# SYSCTRL_PADCONF_CORE register map
Vendor: Texas Instruments
Registers are 32-bit, access per field, reset 0x10F010F unless marked. A register's access mark holds for its fields unless they carry their own. Offsets are as the file gives them; [hi:lo] are bit positions; 'fields as' and 'values as' point back to an identical list.

## SYSCTRL_PADCONF_CORE (part 8 of 10)
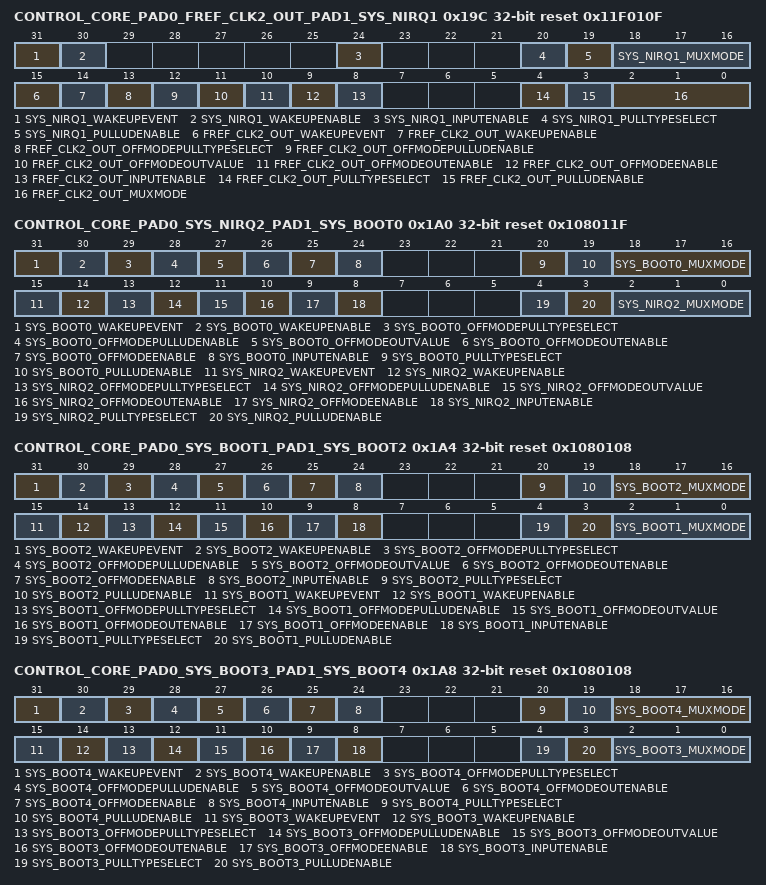
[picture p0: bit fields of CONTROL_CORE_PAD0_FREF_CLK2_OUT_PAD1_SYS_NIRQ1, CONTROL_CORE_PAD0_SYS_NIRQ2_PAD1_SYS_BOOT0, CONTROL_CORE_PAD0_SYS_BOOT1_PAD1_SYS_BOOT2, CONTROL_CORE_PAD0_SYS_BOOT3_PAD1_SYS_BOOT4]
0x19C CONTROL_CORE_PAD0_FREF_CLK2_OUT_PAD1_SYS_NIRQ1 reset 0x11F010F — Register control for Pads fref_clk2_out and sys_nirq1 Access conditions. Read: unrestricted, Write: unrestricted
  [31] SYS_NIRQ1_WAKEUPEVENT ro — Pad_x wake-up event status latched in the IO
    0=SYS_NIRQ1_WAKEUPEVENT_0_r (No wake-up event occurred); 1=SYS_NIRQ1_WAKEUPEVENT_1_r (A wake-up event occurred)
  [30] SYS_NIRQ1_WAKEUPENABLE rw — Input pad wake-up enable (and OFF mode input enable value)
    0=wake-up detection is disabled; 1=wake-up detection is enabled
  [24] SYS_NIRQ1_INPUTENABLE rw — Input enable value for pad sys_nirq1
    0=Input buffer of I/O cell is disabled; 1=Input buffer of I/O cell is enabled
  [20] SYS_NIRQ1_PULLTYPESELECT rw — pullup/down selection for pad sys_nirq1
    0=pulldown selected; 1=pullup selected
  [19] SYS_NIRQ1_PULLUDENABLE rw — pullup/down enable for pad sys_nirq1
    0=pullup/down disabled; 1=pullup/down enabled
  [18:16] SYS_NIRQ1_MUXMODE rw — Functional multiplexing selection for pad sys_nirq1
    0=Select sys_nirq1; 7=Select safe_mode
  [15] FREF_CLK2_OUT_WAKEUPEVENT ro — Pad_x wake-up event status latched in the IO
    0=FREF_CLK2_OUT_WAKEUPEVENT_0_r (No wake-up event occurred); 1=FREF_CLK2_OUT_WAKEUPEVENT_1_r (A wake-up event occurred)
  [14] FREF_CLK2_OUT_WAKEUPENABLE rw — Input pad wake-up enable (and OFF mode input enable value)
    values as SYS_NIRQ1_WAKEUPENABLE
  [13] FREF_CLK2_OUT_OFFMODEPULLTYPESELECT rw — OffMode mode pullup/down selection for pad fref_clk2_out
    0=Offmode pulldown selected; 1=Offmode pullup selected
  [12] FREF_CLK2_OUT_OFFMODEPULLUDENABLE rw — OffMode mode pullup/down enable for pad fref_clk2_out
    0=Offmode pullup/down disabled; 1=Offmode pullup/down enabled
  [11] FREF_CLK2_OUT_OFFMODEOUTVALUE rw — OffMode mode output value for pad fref_clk2_out
    0=Set value at 0; 1=Set value at 1
  [10] FREF_CLK2_OUT_OFFMODEOUTENABLE rw — OffMode mode output enable value for pad fref_clk2_out. This is an active low signal
    0=Output enable; 1=Output disable
  [9] FREF_CLK2_OUT_OFFMODEENABLE rw — OffMode mode override control for pad fref_clk2_out
    0=I/O state keeps its previous state when OFF mode is active; 1=I/O state is forced to OFF mode value when OFF mode is active
  [8] FREF_CLK2_OUT_INPUTENABLE rw — Input enable value for pad fref_clk2_out
    values as SYS_NIRQ1_INPUTENABLE
  [4] FREF_CLK2_OUT_PULLTYPESELECT rw — pullup/down selection for pad fref_clk2_out
    0=pulldown selected; 1=pullup selected
  [3] FREF_CLK2_OUT_PULLUDENABLE rw — pullup/down enable for pad fref_clk2_out
    0=pullup/down disabled; 1=pullup/down enabled
  [2:0] FREF_CLK2_OUT_MUXMODE rw — Functional multiplexing selection for pad fref_clk2_out
    0=Select fref_clk2_out; 3=Select gpio_182; 7=Select safe_mode
0x1A0 CONTROL_CORE_PAD0_SYS_NIRQ2_PAD1_SYS_BOOT0 reset 0x108011F — Register control for Pads sys_nirq2 and sys_boot0 Access conditions. Read: unrestricted, Write: unrestricted
  [31] SYS_BOOT0_WAKEUPEVENT ro — Pad_x wake-up event status latched in the IO
    0=SYS_BOOT0_WAKEUPEVENT_0_r (No wake-up event occurred); 1=SYS_BOOT0_WAKEUPEVENT_1_r (A wake-up event occurred)
  [30] SYS_BOOT0_WAKEUPENABLE rw — Input pad wake-up enable (and OFF mode input enable value)
    values as CONTROL_CORE_PAD0_FREF_CLK2_OUT_PAD1_SYS_NIRQ1.SYS_NIRQ1_WAKEUPENABLE
  [29] SYS_BOOT0_OFFMODEPULLTYPESELECT rw — OffMode mode pullup/down selection for pad sys_boot0
    0=Offmode pulldown selected; 1=Offmode pullup selected
  [28] SYS_BOOT0_OFFMODEPULLUDENABLE rw — OffMode mode pullup/down enable for pad sys_boot0
    values as CONTROL_CORE_PAD0_FREF_CLK2_OUT_PAD1_SYS_NIRQ1.FREF_CLK2_OUT_OFFMODEPULLUDENABLE
  [27] SYS_BOOT0_OFFMODEOUTVALUE rw — OffMode mode output value for pad sys_boot0
    0=Set value at 0; 1=Set value at 1
  [26] SYS_BOOT0_OFFMODEOUTENABLE rw — OffMode mode output enable value for pad sys_boot0. This is an active low signal
    0=Output enable; 1=Output disable
  [25] SYS_BOOT0_OFFMODEENABLE rw — OffMode mode override control for pad sys_boot0
    values as CONTROL_CORE_PAD0_FREF_CLK2_OUT_PAD1_SYS_NIRQ1.FREF_CLK2_OUT_OFFMODEENABLE
  [24] SYS_BOOT0_INPUTENABLE rw — Input enable value for pad sys_boot0
    values as CONTROL_CORE_PAD0_FREF_CLK2_OUT_PAD1_SYS_NIRQ1.SYS_NIRQ1_INPUTENABLE
  [20] SYS_BOOT0_PULLTYPESELECT rw — pullup/down selection for pad sys_boot0
    0=pulldown selected; 1=pullup selected
  [19] SYS_BOOT0_PULLUDENABLE rw — pullup/down enable for pad sys_boot0
    0=pullup/down disabled; 1=pullup/down enabled
  [18:16] SYS_BOOT0_MUXMODE rw — Functional multiplexing selection for pad sys_boot0
    0=Select sys_boot0; 3=Select gpio_184; 7=Select safe_mode
  [15] SYS_NIRQ2_WAKEUPEVENT ro — Pad_x wake-up event status latched in the IO
    0=SYS_NIRQ2_WAKEUPEVENT_0_r (No wake-up event occurred); 1=SYS_NIRQ2_WAKEUPEVENT_1_r (A wake-up event occurred)
  [14] SYS_NIRQ2_WAKEUPENABLE rw — Input pad wake-up enable (and OFF mode input enable value)
    values as CONTROL_CORE_PAD0_FREF_CLK2_OUT_PAD1_SYS_NIRQ1.SYS_NIRQ1_WAKEUPENABLE
  [13] SYS_NIRQ2_OFFMODEPULLTYPESELECT rw — OffMode mode pullup/down selection for pad sys_nirq2
    0=Offmode pulldown selected; 1=Offmode pullup selected
  [12] SYS_NIRQ2_OFFMODEPULLUDENABLE rw — OffMode mode pullup/down enable for pad sys_nirq2
    values as CONTROL_CORE_PAD0_FREF_CLK2_OUT_PAD1_SYS_NIRQ1.FREF_CLK2_OUT_OFFMODEPULLUDENABLE
  [11] SYS_NIRQ2_OFFMODEOUTVALUE rw — OffMode mode output value for pad sys_nirq2
    0=Set value at 0; 1=Set value at 1
  [10] SYS_NIRQ2_OFFMODEOUTENABLE rw — OffMode mode output enable value for pad sys_nirq2. This is an active low signal
    0=Output enable; 1=Output disable
  [9] SYS_NIRQ2_OFFMODEENABLE rw — OffMode mode override control for pad sys_nirq2
    values as CONTROL_CORE_PAD0_FREF_CLK2_OUT_PAD1_SYS_NIRQ1.FREF_CLK2_OUT_OFFMODEENABLE
  [8] SYS_NIRQ2_INPUTENABLE rw — Input enable value for pad sys_nirq2
    values as CONTROL_CORE_PAD0_FREF_CLK2_OUT_PAD1_SYS_NIRQ1.SYS_NIRQ1_INPUTENABLE
  [4] SYS_NIRQ2_PULLTYPESELECT rw — pullup/down selection for pad sys_nirq2
    0=pulldown selected; 1=pullup selected
  [3] SYS_NIRQ2_PULLUDENABLE rw — pullup/down enable for pad sys_nirq2
    0=pullup/down disabled; 1=pullup/down enabled
  [2:0] SYS_NIRQ2_MUXMODE rw — Functional multiplexing selection for pad sys_nirq2
    0=Select sys_nirq2; 3=Select gpio_183; 7=Select safe_mode
0x1A4 CONTROL_CORE_PAD0_SYS_BOOT1_PAD1_SYS_BOOT2 reset 0x1080108 — Register control for Pads sys_boot1 and sys_boot2 Access conditions. Read: unrestricted, Write: unrestricted
  [31] SYS_BOOT2_WAKEUPEVENT ro — Pad_x wake-up event status latched in the IO
    0=SYS_BOOT2_WAKEUPEVENT_0_r (No wake-up event occurred); 1=SYS_BOOT2_WAKEUPEVENT_1_r (A wake-up event occurred)
  [30] SYS_BOOT2_WAKEUPENABLE rw — Input pad wake-up enable (and OFF mode input enable value)
    values as CONTROL_CORE_PAD0_FREF_CLK2_OUT_PAD1_SYS_NIRQ1.SYS_NIRQ1_WAKEUPENABLE
  [29] SYS_BOOT2_OFFMODEPULLTYPESELECT rw — OffMode mode pullup/down selection for pad sys_boot2
    0=Offmode pulldown selected; 1=Offmode pullup selected
  [28] SYS_BOOT2_OFFMODEPULLUDENABLE rw — OffMode mode pullup/down enable for pad sys_boot2
    values as CONTROL_CORE_PAD0_FREF_CLK2_OUT_PAD1_SYS_NIRQ1.FREF_CLK2_OUT_OFFMODEPULLUDENABLE
  [27] SYS_BOOT2_OFFMODEOUTVALUE rw — OffMode mode output value for pad sys_boot2
    0=Set value at 0; 1=Set value at 1
  [26] SYS_BOOT2_OFFMODEOUTENABLE rw — OffMode mode output enable value for pad sys_boot2. This is an active low signal
    0=Output enable; 1=Output disable
  [25] SYS_BOOT2_OFFMODEENABLE rw — OffMode mode override control for pad sys_boot2
    values as CONTROL_CORE_PAD0_FREF_CLK2_OUT_PAD1_SYS_NIRQ1.FREF_CLK2_OUT_OFFMODEENABLE
  [24] SYS_BOOT2_INPUTENABLE rw — Input enable value for pad sys_boot2
    values as CONTROL_CORE_PAD0_FREF_CLK2_OUT_PAD1_SYS_NIRQ1.SYS_NIRQ1_INPUTENABLE
  [20] SYS_BOOT2_PULLTYPESELECT rw — pullup/down selection for pad sys_boot2
    0=pulldown selected; 1=pullup selected
  [19] SYS_BOOT2_PULLUDENABLE rw — pullup/down enable for pad sys_boot2
    0=pullup/down disabled; 1=pullup/down enabled
  [18:16] SYS_BOOT2_MUXMODE rw — Functional multiplexing selection for pad sys_boot2
    0=Select sys_boot2; 3=Select gpio_186; 7=Select safe_mode
  [15] SYS_BOOT1_WAKEUPEVENT ro — Pad_x wake-up event status latched in the IO
    0=SYS_BOOT1_WAKEUPEVENT_0_r (No wake-up event occurred); 1=SYS_BOOT1_WAKEUPEVENT_1_r (A wake-up event occurred)
  [14] SYS_BOOT1_WAKEUPENABLE rw — Input pad wake-up enable (and OFF mode input enable value)
    values as CONTROL_CORE_PAD0_FREF_CLK2_OUT_PAD1_SYS_NIRQ1.SYS_NIRQ1_WAKEUPENABLE
  [13] SYS_BOOT1_OFFMODEPULLTYPESELECT rw — OffMode mode pullup/down selection for pad sys_boot1
    0=Offmode pulldown selected; 1=Offmode pullup selected
  [12] SYS_BOOT1_OFFMODEPULLUDENABLE rw — OffMode mode pullup/down enable for pad sys_boot1
    values as CONTROL_CORE_PAD0_FREF_CLK2_OUT_PAD1_SYS_NIRQ1.FREF_CLK2_OUT_OFFMODEPULLUDENABLE
  [11] SYS_BOOT1_OFFMODEOUTVALUE rw — OffMode mode output value for pad sys_boot1
    0=Set value at 0; 1=Set value at 1
  [10] SYS_BOOT1_OFFMODEOUTENABLE rw — OffMode mode output enable value for pad sys_boot1. This is an active low signal
    0=Output enable; 1=Output disable
  [9] SYS_BOOT1_OFFMODEENABLE rw — OffMode mode override control for pad sys_boot1
    values as CONTROL_CORE_PAD0_FREF_CLK2_OUT_PAD1_SYS_NIRQ1.FREF_CLK2_OUT_OFFMODEENABLE
  [8] SYS_BOOT1_INPUTENABLE rw — Input enable value for pad sys_boot1
    values as CONTROL_CORE_PAD0_FREF_CLK2_OUT_PAD1_SYS_NIRQ1.SYS_NIRQ1_INPUTENABLE
  [4] SYS_BOOT1_PULLTYPESELECT rw — pullup/down selection for pad sys_boot1
    0=pulldown selected; 1=pullup selected
  [3] SYS_BOOT1_PULLUDENABLE rw — pullup/down enable for pad sys_boot1
    0=pullup/down disabled; 1=pullup/down enabled
  [2:0] SYS_BOOT1_MUXMODE rw — Functional multiplexing selection for pad sys_boot1
    0=Select sys_boot1; 3=Select gpio_185; 7=Select safe_mode
0x1A8 CONTROL_CORE_PAD0_SYS_BOOT3_PAD1_SYS_BOOT4 reset 0x1080108 — Register control for Pads sys_boot3 and sys_boot4 Access conditions. Read: unrestricted, Write: unrestricted
  [31] SYS_BOOT4_WAKEUPEVENT ro — Pad_x wake-up event status latched in the IO
    0=SYS_BOOT4_WAKEUPEVENT_0_r (No wake-up event occurred); 1=SYS_BOOT4_WAKEUPEVENT_1_r (A wake-up event occurred)
  [30] SYS_BOOT4_WAKEUPENABLE rw — Input pad wake-up enable (and OFF mode input enable value)
    values as CONTROL_CORE_PAD0_FREF_CLK2_OUT_PAD1_SYS_NIRQ1.SYS_NIRQ1_WAKEUPENABLE
  [29] SYS_BOOT4_OFFMODEPULLTYPESELECT rw — OffMode mode pullup/down selection for pad sys_boot4
    0=Offmode pulldown selected; 1=Offmode pullup selected
  [28] SYS_BOOT4_OFFMODEPULLUDENABLE rw — OffMode mode pullup/down enable for pad sys_boot4
    values as CONTROL_CORE_PAD0_FREF_CLK2_OUT_PAD1_SYS_NIRQ1.FREF_CLK2_OUT_OFFMODEPULLUDENABLE
  [27] SYS_BOOT4_OFFMODEOUTVALUE rw — OffMode mode output value for pad sys_boot4
    0=Set value at 0; 1=Set value at 1
  [26] SYS_BOOT4_OFFMODEOUTENABLE rw — OffMode mode output enable value for pad sys_boot4. This is an active low signal
    0=Output enable; 1=Output disable
  [25] SYS_BOOT4_OFFMODEENABLE rw — OffMode mode override control for pad sys_boot4
    values as CONTROL_CORE_PAD0_FREF_CLK2_OUT_PAD1_SYS_NIRQ1.FREF_CLK2_OUT_OFFMODEENABLE
  [24] SYS_BOOT4_INPUTENABLE rw — Input enable value for pad sys_boot4
    values as CONTROL_CORE_PAD0_FREF_CLK2_OUT_PAD1_SYS_NIRQ1.SYS_NIRQ1_INPUTENABLE
  [20] SYS_BOOT4_PULLTYPESELECT rw — pullup/down selection for pad sys_boot4
    0=pulldown selected; 1=pullup selected
  [19] SYS_BOOT4_PULLUDENABLE rw — pullup/down enable for pad sys_boot4
    0=pullup/down disabled; 1=pullup/down enabled
  [18:16] SYS_BOOT4_MUXMODE rw — Functional multiplexing selection for pad sys_boot4
    0=Select sys_boot4; 3=Select gpio_188; 7=Select safe_mode
  [15] SYS_BOOT3_WAKEUPEVENT ro — Pad_x wake-up event status latched in the IO
    0=SYS_BOOT3_WAKEUPEVENT_0_r (No wake-up event occurred); 1=SYS_BOOT3_WAKEUPEVENT_1_r (A wake-up event occurred)
  [14] SYS_BOOT3_WAKEUPENABLE rw — Input pad wake-up enable (and OFF mode input enable value)
    values as CONTROL_CORE_PAD0_FREF_CLK2_OUT_PAD1_SYS_NIRQ1.SYS_NIRQ1_WAKEUPENABLE
  [13] SYS_BOOT3_OFFMODEPULLTYPESELECT rw — OffMode mode pullup/down selection for pad sys_boot3
    0=Offmode pulldown selected; 1=Offmode pullup selected
  [12] SYS_BOOT3_OFFMODEPULLUDENABLE rw — OffMode mode pullup/down enable for pad sys_boot3
    values as CONTROL_CORE_PAD0_FREF_CLK2_OUT_PAD1_SYS_NIRQ1.FREF_CLK2_OUT_OFFMODEPULLUDENABLE
  [11] SYS_BOOT3_OFFMODEOUTVALUE rw — OffMode mode output value for pad sys_boot3
    0=Set value at 0; 1=Set value at 1
  [10] SYS_BOOT3_OFFMODEOUTENABLE rw — OffMode mode output enable value for pad sys_boot3. This is an active low signal
    0=Output enable; 1=Output disable
  [9] SYS_BOOT3_OFFMODEENABLE rw — OffMode mode override control for pad sys_boot3
    values as CONTROL_CORE_PAD0_FREF_CLK2_OUT_PAD1_SYS_NIRQ1.FREF_CLK2_OUT_OFFMODEENABLE
  [8] SYS_BOOT3_INPUTENABLE rw — Input enable value for pad sys_boot3
    values as CONTROL_CORE_PAD0_FREF_CLK2_OUT_PAD1_SYS_NIRQ1.SYS_NIRQ1_INPUTENABLE
  [4] SYS_BOOT3_PULLTYPESELECT rw — pullup/down selection for pad sys_boot3
    0=pulldown selected; 1=pullup selected
  [3] SYS_BOOT3_PULLUDENABLE rw — pullup/down enable for pad sys_boot3
    0=pullup/down disabled; 1=pullup/down enabled
  [2:0] SYS_BOOT3_MUXMODE rw — Functional multiplexing selection for pad sys_boot3
    0=Select sys_boot3; 3=Select gpio_187; 7=Select safe_mode
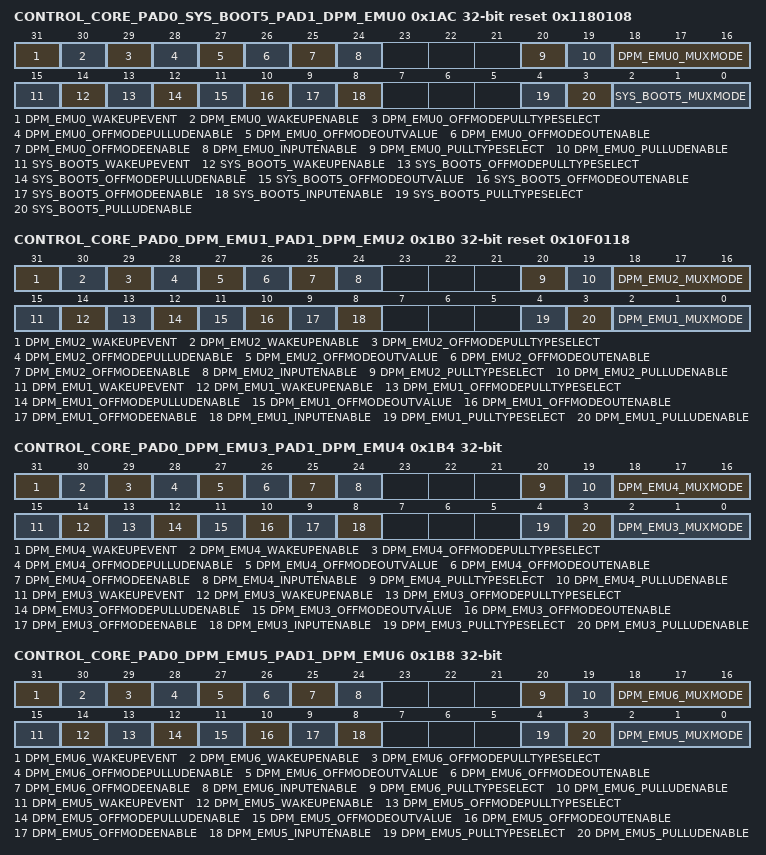
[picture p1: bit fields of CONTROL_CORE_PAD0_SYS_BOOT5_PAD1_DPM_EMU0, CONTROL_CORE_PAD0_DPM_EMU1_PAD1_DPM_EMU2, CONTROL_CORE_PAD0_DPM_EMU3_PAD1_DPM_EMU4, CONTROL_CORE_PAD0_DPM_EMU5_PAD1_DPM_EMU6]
0x1AC CONTROL_CORE_PAD0_SYS_BOOT5_PAD1_DPM_EMU0 reset 0x1180108 — Register control for Pads sys_boot5 and dpm_emu0 Access conditions. Read: unrestricted, Write: unrestricted
  [31] DPM_EMU0_WAKEUPEVENT ro — Pad_x wake-up event status latched in the IO
    0=DPM_EMU0_WAKEUPEVENT_0_r (No wake-up event occurred); 1=DPM_EMU0_WAKEUPEVENT_1_r (A wake-up event occurred)
  [30] DPM_EMU0_WAKEUPENABLE rw — Input pad wake-up enable (and OFF mode input enable value)
    values as CONTROL_CORE_PAD0_FREF_CLK2_OUT_PAD1_SYS_NIRQ1.SYS_NIRQ1_WAKEUPENABLE
  [29] DPM_EMU0_OFFMODEPULLTYPESELECT rw — OffMode mode pullup/down selection for pad dpm_emu0
    0=Offmode pulldown selected; 1=Offmode pullup selected
  [28] DPM_EMU0_OFFMODEPULLUDENABLE rw — OffMode mode pullup/down enable for pad dpm_emu0
    values as CONTROL_CORE_PAD0_FREF_CLK2_OUT_PAD1_SYS_NIRQ1.FREF_CLK2_OUT_OFFMODEPULLUDENABLE
  [27] DPM_EMU0_OFFMODEOUTVALUE rw — OffMode mode output value for pad dpm_emu0
    0=Set value at 0; 1=Set value at 1
  [26] DPM_EMU0_OFFMODEOUTENABLE rw — OffMode mode output enable value for pad dpm_emu0. This is an active low signal
    0=Output enable; 1=Output disable
  [25] DPM_EMU0_OFFMODEENABLE rw — OffMode mode override control for pad dpm_emu0
    values as CONTROL_CORE_PAD0_FREF_CLK2_OUT_PAD1_SYS_NIRQ1.FREF_CLK2_OUT_OFFMODEENABLE
  [24] DPM_EMU0_INPUTENABLE rw — Input enable value for pad dpm_emu0
    values as CONTROL_CORE_PAD0_FREF_CLK2_OUT_PAD1_SYS_NIRQ1.SYS_NIRQ1_INPUTENABLE
  [20] DPM_EMU0_PULLTYPESELECT rw — pullup/down selection for pad dpm_emu0
    0=pulldown selected; 1=pullup selected
  [19] DPM_EMU0_PULLUDENABLE rw — pullup/down enable for pad dpm_emu0
    0=pullup/down disabled; 1=pullup/down enabled
  [18:16] DPM_EMU0_MUXMODE rw — Functional multiplexing selection for pad dpm_emu0
    0=Select dpm_emu0; 3=Select gpio_11; 6=Select hw_dbg0; 7=Select safe_mode
  [15] SYS_BOOT5_WAKEUPEVENT ro — Pad_x wake-up event status latched in the IO
    0=SYS_BOOT5_WAKEUPEVENT_0_r (No wake-up event occurred); 1=SYS_BOOT5_WAKEUPEVENT_1_r (A wake-up event occurred)
  [14] SYS_BOOT5_WAKEUPENABLE rw — Input pad wake-up enable (and OFF mode input enable value)
    values as CONTROL_CORE_PAD0_FREF_CLK2_OUT_PAD1_SYS_NIRQ1.SYS_NIRQ1_WAKEUPENABLE
  [13] SYS_BOOT5_OFFMODEPULLTYPESELECT rw — OffMode mode pullup/down selection for pad sys_boot5
    0=Offmode pulldown selected; 1=Offmode pullup selected
  [12] SYS_BOOT5_OFFMODEPULLUDENABLE rw — OffMode mode pullup/down enable for pad sys_boot5
    values as CONTROL_CORE_PAD0_FREF_CLK2_OUT_PAD1_SYS_NIRQ1.FREF_CLK2_OUT_OFFMODEPULLUDENABLE
  [11] SYS_BOOT5_OFFMODEOUTVALUE rw — OffMode mode output value for pad sys_boot5
    0=Set value at 0; 1=Set value at 1
  [10] SYS_BOOT5_OFFMODEOUTENABLE rw — OffMode mode output enable value for pad sys_boot5. This is an active low signal
    0=Output enable; 1=Output disable
  [9] SYS_BOOT5_OFFMODEENABLE rw — OffMode mode override control for pad sys_boot5
    values as CONTROL_CORE_PAD0_FREF_CLK2_OUT_PAD1_SYS_NIRQ1.FREF_CLK2_OUT_OFFMODEENABLE
  [8] SYS_BOOT5_INPUTENABLE rw — Input enable value for pad sys_boot5
    values as CONTROL_CORE_PAD0_FREF_CLK2_OUT_PAD1_SYS_NIRQ1.SYS_NIRQ1_INPUTENABLE
  [4] SYS_BOOT5_PULLTYPESELECT rw — pullup/down selection for pad sys_boot5
    0=pulldown selected; 1=pullup selected
  [3] SYS_BOOT5_PULLUDENABLE rw — pullup/down enable for pad sys_boot5
    0=pullup/down disabled; 1=pullup/down enabled
  [2:0] SYS_BOOT5_MUXMODE rw — Functional multiplexing selection for pad sys_boot5
    0=Select sys_boot5; 3=Select gpio_189; 7=Select safe_mode
0x1B0 CONTROL_CORE_PAD0_DPM_EMU1_PAD1_DPM_EMU2 reset 0x10F0118 — Register control for Pads dpm_emu1 and dpm_emu2 Access conditions. Read: unrestricted, Write: unrestricted
  [31] DPM_EMU2_WAKEUPEVENT ro — Pad_x wake-up event status latched in the IO
    0=DPM_EMU2_WAKEUPEVENT_0_r (No wake-up event occurred); 1=DPM_EMU2_WAKEUPEVENT_1_r (A wake-up event occurred)
  [30] DPM_EMU2_WAKEUPENABLE rw — Input pad wake-up enable (and OFF mode input enable value)
    values as CONTROL_CORE_PAD0_FREF_CLK2_OUT_PAD1_SYS_NIRQ1.SYS_NIRQ1_WAKEUPENABLE
  [29] DPM_EMU2_OFFMODEPULLTYPESELECT rw — OffMode mode pullup/down selection for pad dpm_emu2
    0=Offmode pulldown selected; 1=Offmode pullup selected
  [28] DPM_EMU2_OFFMODEPULLUDENABLE rw — OffMode mode pullup/down enable for pad dpm_emu2
    values as CONTROL_CORE_PAD0_FREF_CLK2_OUT_PAD1_SYS_NIRQ1.FREF_CLK2_OUT_OFFMODEPULLUDENABLE
  [27] DPM_EMU2_OFFMODEOUTVALUE rw — OffMode mode output value for pad dpm_emu2
    0=Set value at 0; 1=Set value at 1
  [26] DPM_EMU2_OFFMODEOUTENABLE rw — OffMode mode output enable value for pad dpm_emu2. This is an active low signal
    0=Output enable; 1=Output disable
  [25] DPM_EMU2_OFFMODEENABLE rw — OffMode mode override control for pad dpm_emu2
    values as CONTROL_CORE_PAD0_FREF_CLK2_OUT_PAD1_SYS_NIRQ1.FREF_CLK2_OUT_OFFMODEENABLE
  [24] DPM_EMU2_INPUTENABLE rw — Input enable value for pad dpm_emu2
    values as CONTROL_CORE_PAD0_FREF_CLK2_OUT_PAD1_SYS_NIRQ1.SYS_NIRQ1_INPUTENABLE
  [20] DPM_EMU2_PULLTYPESELECT rw — pullup/down selection for pad dpm_emu2
    0=pulldown selected; 1=pullup selected
  [19] DPM_EMU2_PULLUDENABLE rw — pullup/down enable for pad dpm_emu2
    0=pullup/down disabled; 1=pullup/down enabled
  [18:16] DPM_EMU2_MUXMODE rw — Functional multiplexing selection for pad dpm_emu2
    0=Select dpm_emu2; 1=Select usba0_ulpiphy_clk; 3=Select gpio_13; 5=Select dispc2_fid; 6=Select hw_dbg2; 7=Select safe_mode
  [15] DPM_EMU1_WAKEUPEVENT ro — Pad_x wake-up event status latched in the IO
    0=DPM_EMU1_WAKEUPEVENT_0_r (No wake-up event occurred); 1=DPM_EMU1_WAKEUPEVENT_1_r (A wake-up event occurred)
  [14] DPM_EMU1_WAKEUPENABLE rw — Input pad wake-up enable (and OFF mode input enable value)
    values as CONTROL_CORE_PAD0_FREF_CLK2_OUT_PAD1_SYS_NIRQ1.SYS_NIRQ1_WAKEUPENABLE
  [13] DPM_EMU1_OFFMODEPULLTYPESELECT rw — OffMode mode pullup/down selection for pad dpm_emu1
    0=Offmode pulldown selected; 1=Offmode pullup selected
  [12] DPM_EMU1_OFFMODEPULLUDENABLE rw — OffMode mode pullup/down enable for pad dpm_emu1
    values as CONTROL_CORE_PAD0_FREF_CLK2_OUT_PAD1_SYS_NIRQ1.FREF_CLK2_OUT_OFFMODEPULLUDENABLE
  [11] DPM_EMU1_OFFMODEOUTVALUE rw — OffMode mode output value for pad dpm_emu1
    0=Set value at 0; 1=Set value at 1
  [10] DPM_EMU1_OFFMODEOUTENABLE rw — OffMode mode output enable value for pad dpm_emu1. This is an active low signal
    0=Output enable; 1=Output disable
  [9] DPM_EMU1_OFFMODEENABLE rw — OffMode mode override control for pad dpm_emu1
    values as CONTROL_CORE_PAD0_FREF_CLK2_OUT_PAD1_SYS_NIRQ1.FREF_CLK2_OUT_OFFMODEENABLE
  [8] DPM_EMU1_INPUTENABLE rw — Input enable value for pad dpm_emu1
    values as CONTROL_CORE_PAD0_FREF_CLK2_OUT_PAD1_SYS_NIRQ1.SYS_NIRQ1_INPUTENABLE
  [4] DPM_EMU1_PULLTYPESELECT rw — pullup/down selection for pad dpm_emu1
    0=pulldown selected; 1=pullup selected
  [3] DPM_EMU1_PULLUDENABLE rw — pullup/down enable for pad dpm_emu1
    0=pullup/down disabled; 1=pullup/down enabled
  [2:0] DPM_EMU1_MUXMODE rw — Functional multiplexing selection for pad dpm_emu1
    0=Select dpm_emu1; 3=Select gpio_12; 6=Select hw_dbg1; 7=Select safe_mode
0x1B4 CONTROL_CORE_PAD0_DPM_EMU3_PAD1_DPM_EMU4 — Register control for Pads dpm_emu3 and dpm_emu4 Access conditions. Read: unrestricted, Write: unrestricted
  [31] DPM_EMU4_WAKEUPEVENT ro — Pad_x wake-up event status latched in the IO
    0=DPM_EMU4_WAKEUPEVENT_0_r (No wake-up event occurred); 1=DPM_EMU4_WAKEUPEVENT_1_r (A wake-up event occurred)
  [30] DPM_EMU4_WAKEUPENABLE rw — Input pad wake-up enable (and OFF mode input enable value)
    values as CONTROL_CORE_PAD0_FREF_CLK2_OUT_PAD1_SYS_NIRQ1.SYS_NIRQ1_WAKEUPENABLE
  [29] DPM_EMU4_OFFMODEPULLTYPESELECT rw — OffMode mode pullup/down selection for pad dpm_emu4
    0=Offmode pulldown selected; 1=Offmode pullup selected
  [28] DPM_EMU4_OFFMODEPULLUDENABLE rw — OffMode mode pullup/down enable for pad dpm_emu4
    values as CONTROL_CORE_PAD0_FREF_CLK2_OUT_PAD1_SYS_NIRQ1.FREF_CLK2_OUT_OFFMODEPULLUDENABLE
  [27] DPM_EMU4_OFFMODEOUTVALUE rw — OffMode mode output value for pad dpm_emu4
    0=Set value at 0; 1=Set value at 1
  [26] DPM_EMU4_OFFMODEOUTENABLE rw — OffMode mode output enable value for pad dpm_emu4. This is an active low signal
    0=Output enable; 1=Output disable
  [25] DPM_EMU4_OFFMODEENABLE rw — OffMode mode override control for pad dpm_emu4
    values as CONTROL_CORE_PAD0_FREF_CLK2_OUT_PAD1_SYS_NIRQ1.FREF_CLK2_OUT_OFFMODEENABLE
  [24] DPM_EMU4_INPUTENABLE rw — Input enable value for pad dpm_emu4
    values as CONTROL_CORE_PAD0_FREF_CLK2_OUT_PAD1_SYS_NIRQ1.SYS_NIRQ1_INPUTENABLE
  [20] DPM_EMU4_PULLTYPESELECT rw — pullup/down selection for pad dpm_emu4
    0=pulldown selected; 1=pullup selected
  [19] DPM_EMU4_PULLUDENABLE rw — pullup/down enable for pad dpm_emu4
    0=pullup/down disabled; 1=pullup/down enabled
  [18:16] DPM_EMU4_MUXMODE rw — Functional multiplexing selection for pad dpm_emu4
    0=Select dpm_emu4; 1=Select usba0_ulpiphy_dir; 3=Select gpio_15; 4=Select rfbi_data9; 5=Select dispc2_data9; 6=Select hw_dbg4; 7=Select safe_mode
  [15] DPM_EMU3_WAKEUPEVENT ro — Pad_x wake-up event status latched in the IO
    0=DPM_EMU3_WAKEUPEVENT_0_r (No wake-up event occurred); 1=DPM_EMU3_WAKEUPEVENT_1_r (A wake-up event occurred)
  [14] DPM_EMU3_WAKEUPENABLE rw — Input pad wake-up enable (and OFF mode input enable value)
    values as CONTROL_CORE_PAD0_FREF_CLK2_OUT_PAD1_SYS_NIRQ1.SYS_NIRQ1_WAKEUPENABLE
  [13] DPM_EMU3_OFFMODEPULLTYPESELECT rw — OffMode mode pullup/down selection for pad dpm_emu3
    0=Offmode pulldown selected; 1=Offmode pullup selected
  [12] DPM_EMU3_OFFMODEPULLUDENABLE rw — OffMode mode pullup/down enable for pad dpm_emu3
    values as CONTROL_CORE_PAD0_FREF_CLK2_OUT_PAD1_SYS_NIRQ1.FREF_CLK2_OUT_OFFMODEPULLUDENABLE
  [11] DPM_EMU3_OFFMODEOUTVALUE rw — OffMode mode output value for pad dpm_emu3
    0=Set value at 0; 1=Set value at 1
  [10] DPM_EMU3_OFFMODEOUTENABLE rw — OffMode mode output enable value for pad dpm_emu3. This is an active low signal
    0=Output enable; 1=Output disable
  [9] DPM_EMU3_OFFMODEENABLE rw — OffMode mode override control for pad dpm_emu3
    values as CONTROL_CORE_PAD0_FREF_CLK2_OUT_PAD1_SYS_NIRQ1.FREF_CLK2_OUT_OFFMODEENABLE
  [8] DPM_EMU3_INPUTENABLE rw — Input enable value for pad dpm_emu3
    values as CONTROL_CORE_PAD0_FREF_CLK2_OUT_PAD1_SYS_NIRQ1.SYS_NIRQ1_INPUTENABLE
  [4] DPM_EMU3_PULLTYPESELECT rw — pullup/down selection for pad dpm_emu3
    0=pulldown selected; 1=pullup selected
  [3] DPM_EMU3_PULLUDENABLE rw — pullup/down enable for pad dpm_emu3
    0=pullup/down disabled; 1=pullup/down enabled
  [2:0] DPM_EMU3_MUXMODE rw — Functional multiplexing selection for pad dpm_emu3
    0=Select dpm_emu3; 1=Select usba0_ulpiphy_stp; 3=Select gpio_14; 4=Select rfbi_data10; 5=Select dispc2_data10; 6=Select hw_dbg3; 7=Select safe_mode
0x1B8 CONTROL_CORE_PAD0_DPM_EMU5_PAD1_DPM_EMU6 — Register control for Pads dpm_emu5 and dpm_emu6 Access conditions. Read: unrestricted, Write: unrestricted
  [31] DPM_EMU6_WAKEUPEVENT ro — Pad_x wake-up event status latched in the IO
    0=DPM_EMU6_WAKEUPEVENT_0_r (No wake-up event occurred); 1=DPM_EMU6_WAKEUPEVENT_1_r (A wake-up event occurred)
  [30] DPM_EMU6_WAKEUPENABLE rw — Input pad wake-up enable (and OFF mode input enable value)
    values as CONTROL_CORE_PAD0_FREF_CLK2_OUT_PAD1_SYS_NIRQ1.SYS_NIRQ1_WAKEUPENABLE
  [29] DPM_EMU6_OFFMODEPULLTYPESELECT rw — OffMode mode pullup/down selection for pad dpm_emu6
    0=Offmode pulldown selected; 1=Offmode pullup selected
  [28] DPM_EMU6_OFFMODEPULLUDENABLE rw — OffMode mode pullup/down enable for pad dpm_emu6
    values as CONTROL_CORE_PAD0_FREF_CLK2_OUT_PAD1_SYS_NIRQ1.FREF_CLK2_OUT_OFFMODEPULLUDENABLE
  [27] DPM_EMU6_OFFMODEOUTVALUE rw — OffMode mode output value for pad dpm_emu6
    0=Set value at 0; 1=Set value at 1
  [26] DPM_EMU6_OFFMODEOUTENABLE rw — OffMode mode output enable value for pad dpm_emu6. This is an active low signal
    0=Output enable; 1=Output disable
  [25] DPM_EMU6_OFFMODEENABLE rw — OffMode mode override control for pad dpm_emu6
    values as CONTROL_CORE_PAD0_FREF_CLK2_OUT_PAD1_SYS_NIRQ1.FREF_CLK2_OUT_OFFMODEENABLE
  [24] DPM_EMU6_INPUTENABLE rw — Input enable value for pad dpm_emu6
    values as CONTROL_CORE_PAD0_FREF_CLK2_OUT_PAD1_SYS_NIRQ1.SYS_NIRQ1_INPUTENABLE
  [20] DPM_EMU6_PULLTYPESELECT rw — pullup/down selection for pad dpm_emu6
    0=pulldown selected; 1=pullup selected
  [19] DPM_EMU6_PULLUDENABLE rw — pullup/down enable for pad dpm_emu6
    0=pullup/down disabled; 1=pullup/down enabled
  [18:16] DPM_EMU6_MUXMODE rw — Functional multiplexing selection for pad dpm_emu6
    0=Select dpm_emu6; 1=Select usba0_ulpiphy_dat0; 2=Select uart3_tx_irtx; 3=Select gpio_17; 4=Select rfbi_hsync0; 5=Select dispc2_data17; 6=Select hw_dbg6; 7=Select safe_mode
  [15] DPM_EMU5_WAKEUPEVENT ro — Pad_x wake-up event status latched in the IO
    0=DPM_EMU5_WAKEUPEVENT_0_r (No wake-up event occurred); 1=DPM_EMU5_WAKEUPEVENT_1_r (A wake-up event occurred)
  [14] DPM_EMU5_WAKEUPENABLE rw — Input pad wake-up enable (and OFF mode input enable value)
    values as CONTROL_CORE_PAD0_FREF_CLK2_OUT_PAD1_SYS_NIRQ1.SYS_NIRQ1_WAKEUPENABLE
  [13] DPM_EMU5_OFFMODEPULLTYPESELECT rw — OffMode mode pullup/down selection for pad dpm_emu5
    0=Offmode pulldown selected; 1=Offmode pullup selected
  [12] DPM_EMU5_OFFMODEPULLUDENABLE rw — OffMode mode pullup/down enable for pad dpm_emu5
    values as CONTROL_CORE_PAD0_FREF_CLK2_OUT_PAD1_SYS_NIRQ1.FREF_CLK2_OUT_OFFMODEPULLUDENABLE
  [11] DPM_EMU5_OFFMODEOUTVALUE rw — OffMode mode output value for pad dpm_emu5
    0=Set value at 0; 1=Set value at 1
  [10] DPM_EMU5_OFFMODEOUTENABLE rw — OffMode mode output enable value for pad dpm_emu5. This is an active low signal
    0=Output enable; 1=Output disable
  [9] DPM_EMU5_OFFMODEENABLE rw — OffMode mode override control for pad dpm_emu5
    values as CONTROL_CORE_PAD0_FREF_CLK2_OUT_PAD1_SYS_NIRQ1.FREF_CLK2_OUT_OFFMODEENABLE
  [8] DPM_EMU5_INPUTENABLE rw — Input enable value for pad dpm_emu5
    values as CONTROL_CORE_PAD0_FREF_CLK2_OUT_PAD1_SYS_NIRQ1.SYS_NIRQ1_INPUTENABLE
  [4] DPM_EMU5_PULLTYPESELECT rw — pullup/down selection for pad dpm_emu5
    0=pulldown selected; 1=pullup selected
  [3] DPM_EMU5_PULLUDENABLE rw — pullup/down enable for pad dpm_emu5
    0=pullup/down disabled; 1=pullup/down enabled
  [2:0] DPM_EMU5_MUXMODE rw — Functional multiplexing selection for pad dpm_emu5
    0=Select dpm_emu5; 1=Select usba0_ulpiphy_nxt; 3=Select gpio_16; 4=Select rfbi_te_vsync0; 5=Select dispc2_data16; 6=Select hw_dbg5; 7=Select safe_mode
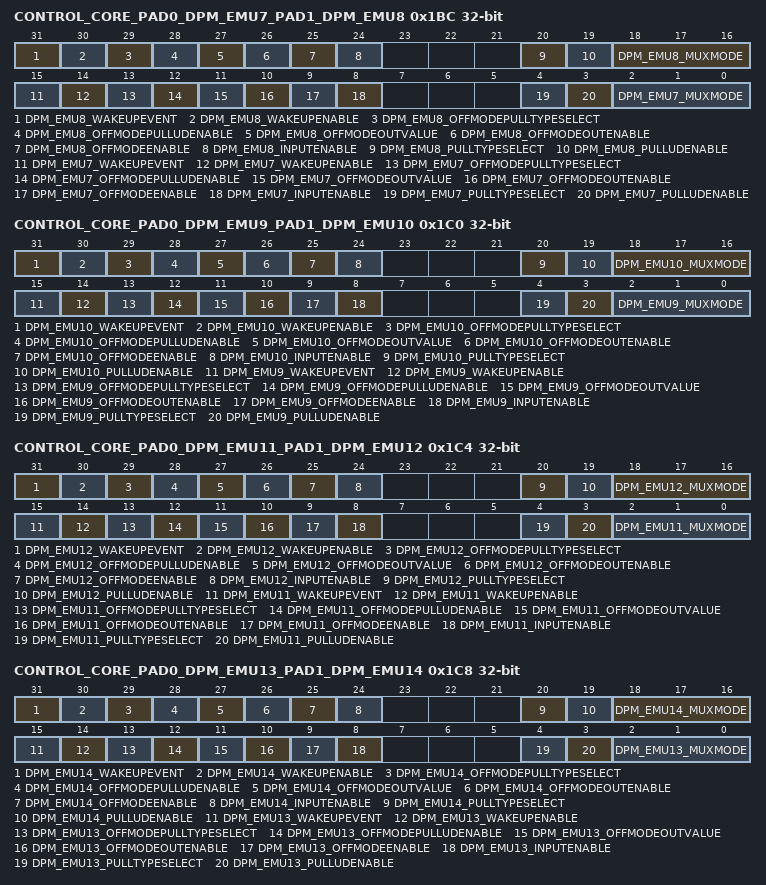
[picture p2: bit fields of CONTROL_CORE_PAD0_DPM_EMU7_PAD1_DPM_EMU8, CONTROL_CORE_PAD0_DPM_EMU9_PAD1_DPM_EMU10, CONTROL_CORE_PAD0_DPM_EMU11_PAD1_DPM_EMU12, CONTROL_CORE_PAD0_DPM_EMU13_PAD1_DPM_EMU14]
0x1BC CONTROL_CORE_PAD0_DPM_EMU7_PAD1_DPM_EMU8 — Register control for Pads dpm_emu7 and dpm_emu8 Access conditions. Read: unrestricted, Write: unrestricted
  [31] DPM_EMU8_WAKEUPEVENT ro — Pad_x wake-up event status latched in the IO
    0=DPM_EMU8_WAKEUPEVENT_0_r (No wake-up event occurred); 1=DPM_EMU8_WAKEUPEVENT_1_r (A wake-up event occurred)
  [30] DPM_EMU8_WAKEUPENABLE rw — Input pad wake-up enable (and OFF mode input enable value)
    values as CONTROL_CORE_PAD0_FREF_CLK2_OUT_PAD1_SYS_NIRQ1.SYS_NIRQ1_WAKEUPENABLE
  [29] DPM_EMU8_OFFMODEPULLTYPESELECT rw — OffMode mode pullup/down selection for pad dpm_emu8
    0=Offmode pulldown selected; 1=Offmode pullup selected
  [28] DPM_EMU8_OFFMODEPULLUDENABLE rw — OffMode mode pullup/down enable for pad dpm_emu8
    values as CONTROL_CORE_PAD0_FREF_CLK2_OUT_PAD1_SYS_NIRQ1.FREF_CLK2_OUT_OFFMODEPULLUDENABLE
  [27] DPM_EMU8_OFFMODEOUTVALUE rw — OffMode mode output value for pad dpm_emu8
    0=Set value at 0; 1=Set value at 1
  [26] DPM_EMU8_OFFMODEOUTENABLE rw — OffMode mode output enable value for pad dpm_emu8. This is an active low signal
    0=Output enable; 1=Output disable
  [25] DPM_EMU8_OFFMODEENABLE rw — OffMode mode override control for pad dpm_emu8
    values as CONTROL_CORE_PAD0_FREF_CLK2_OUT_PAD1_SYS_NIRQ1.FREF_CLK2_OUT_OFFMODEENABLE
  [24] DPM_EMU8_INPUTENABLE rw — Input enable value for pad dpm_emu8
    values as CONTROL_CORE_PAD0_FREF_CLK2_OUT_PAD1_SYS_NIRQ1.SYS_NIRQ1_INPUTENABLE
  [20] DPM_EMU8_PULLTYPESELECT rw — pullup/down selection for pad dpm_emu8
    0=pulldown selected; 1=pullup selected
  [19] DPM_EMU8_PULLUDENABLE rw — pullup/down enable for pad dpm_emu8
    0=pullup/down disabled; 1=pullup/down enabled
  [18:16] DPM_EMU8_MUXMODE rw — Functional multiplexing selection for pad dpm_emu8
    0=Select dpm_emu8; 1=Select usba0_ulpiphy_dat2; 2=Select uart3_rts_sd; 3=Select gpio_19; 4=Select rfbi_re; 5=Select dispc2_pclk; 6=Select hw_dbg8; 7=Select safe_mode
  [15] DPM_EMU7_WAKEUPEVENT ro — Pad_x wake-up event status latched in the IO
    0=DPM_EMU7_WAKEUPEVENT_0_r (No wake-up event occurred); 1=DPM_EMU7_WAKEUPEVENT_1_r (A wake-up event occurred)
  [14] DPM_EMU7_WAKEUPENABLE rw — Input pad wake-up enable (and OFF mode input enable value)
    values as CONTROL_CORE_PAD0_FREF_CLK2_OUT_PAD1_SYS_NIRQ1.SYS_NIRQ1_WAKEUPENABLE
  [13] DPM_EMU7_OFFMODEPULLTYPESELECT rw — OffMode mode pullup/down selection for pad dpm_emu7
    0=Offmode pulldown selected; 1=Offmode pullup selected
  [12] DPM_EMU7_OFFMODEPULLUDENABLE rw — OffMode mode pullup/down enable for pad dpm_emu7
    values as CONTROL_CORE_PAD0_FREF_CLK2_OUT_PAD1_SYS_NIRQ1.FREF_CLK2_OUT_OFFMODEPULLUDENABLE
  [11] DPM_EMU7_OFFMODEOUTVALUE rw — OffMode mode output value for pad dpm_emu7
    0=Set value at 0; 1=Set value at 1
  [10] DPM_EMU7_OFFMODEOUTENABLE rw — OffMode mode output enable value for pad dpm_emu7. This is an active low signal
    0=Output enable; 1=Output disable
  [9] DPM_EMU7_OFFMODEENABLE rw — OffMode mode override control for pad dpm_emu7
    values as CONTROL_CORE_PAD0_FREF_CLK2_OUT_PAD1_SYS_NIRQ1.FREF_CLK2_OUT_OFFMODEENABLE
  [8] DPM_EMU7_INPUTENABLE rw — Input enable value for pad dpm_emu7
    values as CONTROL_CORE_PAD0_FREF_CLK2_OUT_PAD1_SYS_NIRQ1.SYS_NIRQ1_INPUTENABLE
  [4] DPM_EMU7_PULLTYPESELECT rw — pullup/down selection for pad dpm_emu7
    0=pulldown selected; 1=pullup selected
  [3] DPM_EMU7_PULLUDENABLE rw — pullup/down enable for pad dpm_emu7
    0=pullup/down disabled; 1=pullup/down enabled
  [2:0] DPM_EMU7_MUXMODE rw — Functional multiplexing selection for pad dpm_emu7
    0=Select dpm_emu7; 1=Select usba0_ulpiphy_dat1; 2=Select uart3_rx_irrx; 3=Select gpio_18; 4=Select rfbi_cs0; 5=Select dispc2_hsync; 6=Select hw_dbg7; 7=Select safe_mode
0x1C0 CONTROL_CORE_PAD0_DPM_EMU9_PAD1_DPM_EMU10 — Register control for Pads dpm_emu9 and dpm_emu10 Access conditions. Read: unrestricted, Write: unrestricted
  [31] DPM_EMU10_WAKEUPEVENT ro — Pad_x wake-up event status latched in the IO
    0=DPM_EMU10_WAKEUPEVENT_0_r (No wake-up event occurred); 1=DPM_EMU10_WAKEUPEVENT_1_r (A wake-up event occurred)
  [30] DPM_EMU10_WAKEUPENABLE rw — Input pad wake-up enable (and OFF mode input enable value)
    values as CONTROL_CORE_PAD0_FREF_CLK2_OUT_PAD1_SYS_NIRQ1.SYS_NIRQ1_WAKEUPENABLE
  [29] DPM_EMU10_OFFMODEPULLTYPESELECT rw — OffMode mode pullup/down selection for pad dpm_emu10
    0=Offmode pulldown selected; 1=Offmode pullup selected
  [28] DPM_EMU10_OFFMODEPULLUDENABLE rw — OffMode mode pullup/down enable for pad dpm_emu10
    values as CONTROL_CORE_PAD0_FREF_CLK2_OUT_PAD1_SYS_NIRQ1.FREF_CLK2_OUT_OFFMODEPULLUDENABLE
  [27] DPM_EMU10_OFFMODEOUTVALUE rw — OffMode mode output value for pad dpm_emu10
    0=Set value at 0; 1=Set value at 1
  [26] DPM_EMU10_OFFMODEOUTENABLE rw — OffMode mode output enable value for pad dpm_emu10. This is an active low signal
    0=Output enable; 1=Output disable
  [25] DPM_EMU10_OFFMODEENABLE rw — OffMode mode override control for pad dpm_emu10
    values as CONTROL_CORE_PAD0_FREF_CLK2_OUT_PAD1_SYS_NIRQ1.FREF_CLK2_OUT_OFFMODEENABLE
  [24] DPM_EMU10_INPUTENABLE rw — Input enable value for pad dpm_emu10
    values as CONTROL_CORE_PAD0_FREF_CLK2_OUT_PAD1_SYS_NIRQ1.SYS_NIRQ1_INPUTENABLE
  [20] DPM_EMU10_PULLTYPESELECT rw — pullup/down selection for pad dpm_emu10
    0=pulldown selected; 1=pullup selected
  [19] DPM_EMU10_PULLUDENABLE rw — pullup/down enable for pad dpm_emu10
    0=pullup/down disabled; 1=pullup/down enabled
  [18:16] DPM_EMU10_MUXMODE rw — Functional multiplexing selection for pad dpm_emu10
    0=Select dpm_emu10; 1=Select usba0_ulpiphy_dat4; 3=Select gpio_21; 4=Select rfbi_a0; 5=Select dispc2_de; 6=Select hw_dbg10; 7=Select safe_mode
  [15] DPM_EMU9_WAKEUPEVENT ro — Pad_x wake-up event status latched in the IO
    0=DPM_EMU9_WAKEUPEVENT_0_r (No wake-up event occurred); 1=DPM_EMU9_WAKEUPEVENT_1_r (A wake-up event occurred)
  [14] DPM_EMU9_WAKEUPENABLE rw — Input pad wake-up enable (and OFF mode input enable value)
    values as CONTROL_CORE_PAD0_FREF_CLK2_OUT_PAD1_SYS_NIRQ1.SYS_NIRQ1_WAKEUPENABLE
  [13] DPM_EMU9_OFFMODEPULLTYPESELECT rw — OffMode mode pullup/down selection for pad dpm_emu9
    0=Offmode pulldown selected; 1=Offmode pullup selected
  [12] DPM_EMU9_OFFMODEPULLUDENABLE rw — OffMode mode pullup/down enable for pad dpm_emu9
    values as CONTROL_CORE_PAD0_FREF_CLK2_OUT_PAD1_SYS_NIRQ1.FREF_CLK2_OUT_OFFMODEPULLUDENABLE
  [11] DPM_EMU9_OFFMODEOUTVALUE rw — OffMode mode output value for pad dpm_emu9
    0=Set value at 0; 1=Set value at 1
  [10] DPM_EMU9_OFFMODEOUTENABLE rw — OffMode mode output enable value for pad dpm_emu9. This is an active low signal
    0=Output enable; 1=Output disable
  [9] DPM_EMU9_OFFMODEENABLE rw — OffMode mode override control for pad dpm_emu9
    values as CONTROL_CORE_PAD0_FREF_CLK2_OUT_PAD1_SYS_NIRQ1.FREF_CLK2_OUT_OFFMODEENABLE
  [8] DPM_EMU9_INPUTENABLE rw — Input enable value for pad dpm_emu9
    values as CONTROL_CORE_PAD0_FREF_CLK2_OUT_PAD1_SYS_NIRQ1.SYS_NIRQ1_INPUTENABLE
  [4] DPM_EMU9_PULLTYPESELECT rw — pullup/down selection for pad dpm_emu9
    0=pulldown selected; 1=pullup selected
  [3] DPM_EMU9_PULLUDENABLE rw — pullup/down enable for pad dpm_emu9
    0=pullup/down disabled; 1=pullup/down enabled
  [2:0] DPM_EMU9_MUXMODE rw — Functional multiplexing selection for pad dpm_emu9
    0=Select dpm_emu9; 1=Select usba0_ulpiphy_dat3; 2=Select uart3_cts_rctx; 3=Select gpio_20; 4=Select rfbi_we; 5=Select dispc2_vsync; 6=Select hw_dbg9; 7=Select safe_mode
0x1C4 CONTROL_CORE_PAD0_DPM_EMU11_PAD1_DPM_EMU12 — Register control for Pads dpm_emu11 and dpm_emu12 Access conditions. Read: unrestricted, Write: unrestricted
  [31] DPM_EMU12_WAKEUPEVENT ro — Pad_x wake-up event status latched in the IO
    0=DPM_EMU12_WAKEUPEVENT_0_r (No wake-up event occurred); 1=DPM_EMU12_WAKEUPEVENT_1_r (A wake-up event occurred)
  [30] DPM_EMU12_WAKEUPENABLE rw — Input pad wake-up enable (and OFF mode input enable value)
    values as CONTROL_CORE_PAD0_FREF_CLK2_OUT_PAD1_SYS_NIRQ1.SYS_NIRQ1_WAKEUPENABLE
  [29] DPM_EMU12_OFFMODEPULLTYPESELECT rw — OffMode mode pullup/down selection for pad dpm_emu12
    0=Offmode pulldown selected; 1=Offmode pullup selected
  [28] DPM_EMU12_OFFMODEPULLUDENABLE rw — OffMode mode pullup/down enable for pad dpm_emu12
    values as CONTROL_CORE_PAD0_FREF_CLK2_OUT_PAD1_SYS_NIRQ1.FREF_CLK2_OUT_OFFMODEPULLUDENABLE
  [27] DPM_EMU12_OFFMODEOUTVALUE rw — OffMode mode output value for pad dpm_emu12
    0=Set value at 0; 1=Set value at 1
  [26] DPM_EMU12_OFFMODEOUTENABLE rw — OffMode mode output enable value for pad dpm_emu12. This is an active low signal
    0=Output enable; 1=Output disable
  [25] DPM_EMU12_OFFMODEENABLE rw — OffMode mode override control for pad dpm_emu12
    values as CONTROL_CORE_PAD0_FREF_CLK2_OUT_PAD1_SYS_NIRQ1.FREF_CLK2_OUT_OFFMODEENABLE
  [24] DPM_EMU12_INPUTENABLE rw — Input enable value for pad dpm_emu12
    values as CONTROL_CORE_PAD0_FREF_CLK2_OUT_PAD1_SYS_NIRQ1.SYS_NIRQ1_INPUTENABLE
  [20] DPM_EMU12_PULLTYPESELECT rw — pullup/down selection for pad dpm_emu12
    0=pulldown selected; 1=pullup selected
  [19] DPM_EMU12_PULLUDENABLE rw — pullup/down enable for pad dpm_emu12
    0=pullup/down disabled; 1=pullup/down enabled
  [18:16] DPM_EMU12_MUXMODE rw — Functional multiplexing selection for pad dpm_emu12
    0=Select dpm_emu12; 1=Select usba0_ulpiphy_dat6; 3=Select gpio_23; 4=Select rfbi_data7; 5=Select dispc2_data7; 6=Select hw_dbg12; 7=Select safe_mode
  [15] DPM_EMU11_WAKEUPEVENT ro — Pad_x wake-up event status latched in the IO
    0=DPM_EMU11_WAKEUPEVENT_0_r (No wake-up event occurred); 1=DPM_EMU11_WAKEUPEVENT_1_r (A wake-up event occurred)
  [14] DPM_EMU11_WAKEUPENABLE rw — Input pad wake-up enable (and OFF mode input enable value)
    values as CONTROL_CORE_PAD0_FREF_CLK2_OUT_PAD1_SYS_NIRQ1.SYS_NIRQ1_WAKEUPENABLE
  [13] DPM_EMU11_OFFMODEPULLTYPESELECT rw — OffMode mode pullup/down selection for pad dpm_emu11
    0=Offmode pulldown selected; 1=Offmode pullup selected
  [12] DPM_EMU11_OFFMODEPULLUDENABLE rw — OffMode mode pullup/down enable for pad dpm_emu11
    values as CONTROL_CORE_PAD0_FREF_CLK2_OUT_PAD1_SYS_NIRQ1.FREF_CLK2_OUT_OFFMODEPULLUDENABLE
  [11] DPM_EMU11_OFFMODEOUTVALUE rw — OffMode mode output value for pad dpm_emu11
    0=Set value at 0; 1=Set value at 1
  [10] DPM_EMU11_OFFMODEOUTENABLE rw — OffMode mode output enable value for pad dpm_emu11. This is an active low signal
    0=Output enable; 1=Output disable
  [9] DPM_EMU11_OFFMODEENABLE rw — OffMode mode override control for pad dpm_emu11
    values as CONTROL_CORE_PAD0_FREF_CLK2_OUT_PAD1_SYS_NIRQ1.FREF_CLK2_OUT_OFFMODEENABLE
  [8] DPM_EMU11_INPUTENABLE rw — Input enable value for pad dpm_emu11
    values as CONTROL_CORE_PAD0_FREF_CLK2_OUT_PAD1_SYS_NIRQ1.SYS_NIRQ1_INPUTENABLE
  [4] DPM_EMU11_PULLTYPESELECT rw — pullup/down selection for pad dpm_emu11
    0=pulldown selected; 1=pullup selected
  [3] DPM_EMU11_PULLUDENABLE rw — pullup/down enable for pad dpm_emu11
    0=pullup/down disabled; 1=pullup/down enabled
  [2:0] DPM_EMU11_MUXMODE rw — Functional multiplexing selection for pad dpm_emu11
    0=Select dpm_emu11; 1=Select usba0_ulpiphy_dat5; 3=Select gpio_22; 4=Select rfbi_data8; 5=Select dispc2_data8; 6=Select hw_dbg11; 7=Select safe_mode
0x1C8 CONTROL_CORE_PAD0_DPM_EMU13_PAD1_DPM_EMU14 — Register control for Pads dpm_emu13 and dpm_emu14 Access conditions. Read: unrestricted, Write: unrestricted
  [31] DPM_EMU14_WAKEUPEVENT ro — Pad_x wake-up event status latched in the IO
    0=DPM_EMU14_WAKEUPEVENT_0_r (No wake-up event occurred); 1=DPM_EMU14_WAKEUPEVENT_1_r (A wake-up event occurred)
  [30] DPM_EMU14_WAKEUPENABLE rw — Input pad wake-up enable (and OFF mode input enable value)
    values as CONTROL_CORE_PAD0_FREF_CLK2_OUT_PAD1_SYS_NIRQ1.SYS_NIRQ1_WAKEUPENABLE
  [29] DPM_EMU14_OFFMODEPULLTYPESELECT rw — OffMode mode pullup/down selection for pad dpm_emu14
    0=Offmode pulldown selected; 1=Offmode pullup selected
  [28] DPM_EMU14_OFFMODEPULLUDENABLE rw — OffMode mode pullup/down enable for pad dpm_emu14
    values as CONTROL_CORE_PAD0_FREF_CLK2_OUT_PAD1_SYS_NIRQ1.FREF_CLK2_OUT_OFFMODEPULLUDENABLE
  [27] DPM_EMU14_OFFMODEOUTVALUE rw — OffMode mode output value for pad dpm_emu14
    0=Set value at 0; 1=Set value at 1
  [26] DPM_EMU14_OFFMODEOUTENABLE rw — OffMode mode output enable value for pad dpm_emu14. This is an active low signal
    0=Output enable; 1=Output disable
  [25] DPM_EMU14_OFFMODEENABLE rw — OffMode mode override control for pad dpm_emu14
    values as CONTROL_CORE_PAD0_FREF_CLK2_OUT_PAD1_SYS_NIRQ1.FREF_CLK2_OUT_OFFMODEENABLE
  [24] DPM_EMU14_INPUTENABLE rw — Input enable value for pad dpm_emu14
    values as CONTROL_CORE_PAD0_FREF_CLK2_OUT_PAD1_SYS_NIRQ1.SYS_NIRQ1_INPUTENABLE
  [20] DPM_EMU14_PULLTYPESELECT rw — pullup/down selection for pad dpm_emu14
    0=pulldown selected; 1=pullup selected
  [19] DPM_EMU14_PULLUDENABLE rw — pullup/down enable for pad dpm_emu14
    0=pullup/down disabled; 1=pullup/down enabled
  [18:16] DPM_EMU14_MUXMODE rw — Functional multiplexing selection for pad dpm_emu14
    0=Select dpm_emu14; 2=Select uart1_rx; 3=Select gpio_25; 4=Select rfbi_data5; 5=Select dispc2_data5; 6=Select hw_dbg14; 7=Select safe_mode
  [15] DPM_EMU13_WAKEUPEVENT ro — Pad_x wake-up event status latched in the IO
    0=DPM_EMU13_WAKEUPEVENT_0_r (No wake-up event occurred); 1=DPM_EMU13_WAKEUPEVENT_1_r (A wake-up event occurred)
  [14] DPM_EMU13_WAKEUPENABLE rw — Input pad wake-up enable (and OFF mode input enable value)
    values as CONTROL_CORE_PAD0_FREF_CLK2_OUT_PAD1_SYS_NIRQ1.SYS_NIRQ1_WAKEUPENABLE
  [13] DPM_EMU13_OFFMODEPULLTYPESELECT rw — OffMode mode pullup/down selection for pad dpm_emu13
    0=Offmode pulldown selected; 1=Offmode pullup selected
  [12] DPM_EMU13_OFFMODEPULLUDENABLE rw — OffMode mode pullup/down enable for pad dpm_emu13
    values as CONTROL_CORE_PAD0_FREF_CLK2_OUT_PAD1_SYS_NIRQ1.FREF_CLK2_OUT_OFFMODEPULLUDENABLE
  [11] DPM_EMU13_OFFMODEOUTVALUE rw — OffMode mode output value for pad dpm_emu13
    0=Set value at 0; 1=Set value at 1
  [10] DPM_EMU13_OFFMODEOUTENABLE rw — OffMode mode output enable value for pad dpm_emu13. This is an active low signal
    0=Output enable; 1=Output disable
  [9] DPM_EMU13_OFFMODEENABLE rw — OffMode mode override control for pad dpm_emu13
    values as CONTROL_CORE_PAD0_FREF_CLK2_OUT_PAD1_SYS_NIRQ1.FREF_CLK2_OUT_OFFMODEENABLE
  [8] DPM_EMU13_INPUTENABLE rw — Input enable value for pad dpm_emu13
    values as CONTROL_CORE_PAD0_FREF_CLK2_OUT_PAD1_SYS_NIRQ1.SYS_NIRQ1_INPUTENABLE
  [4] DPM_EMU13_PULLTYPESELECT rw — pullup/down selection for pad dpm_emu13
    0=pulldown selected; 1=pullup selected
  [3] DPM_EMU13_PULLUDENABLE rw — pullup/down enable for pad dpm_emu13
    0=pullup/down disabled; 1=pullup/down enabled
  [2:0] DPM_EMU13_MUXMODE rw — Functional multiplexing selection for pad dpm_emu13
    0=Select dpm_emu13; 1=Select usba0_ulpiphy_dat7; 3=Select gpio_24; 4=Select rfbi_data6; 5=Select dispc2_data6; 6=Select hw_dbg13; 7=Select safe_mode
